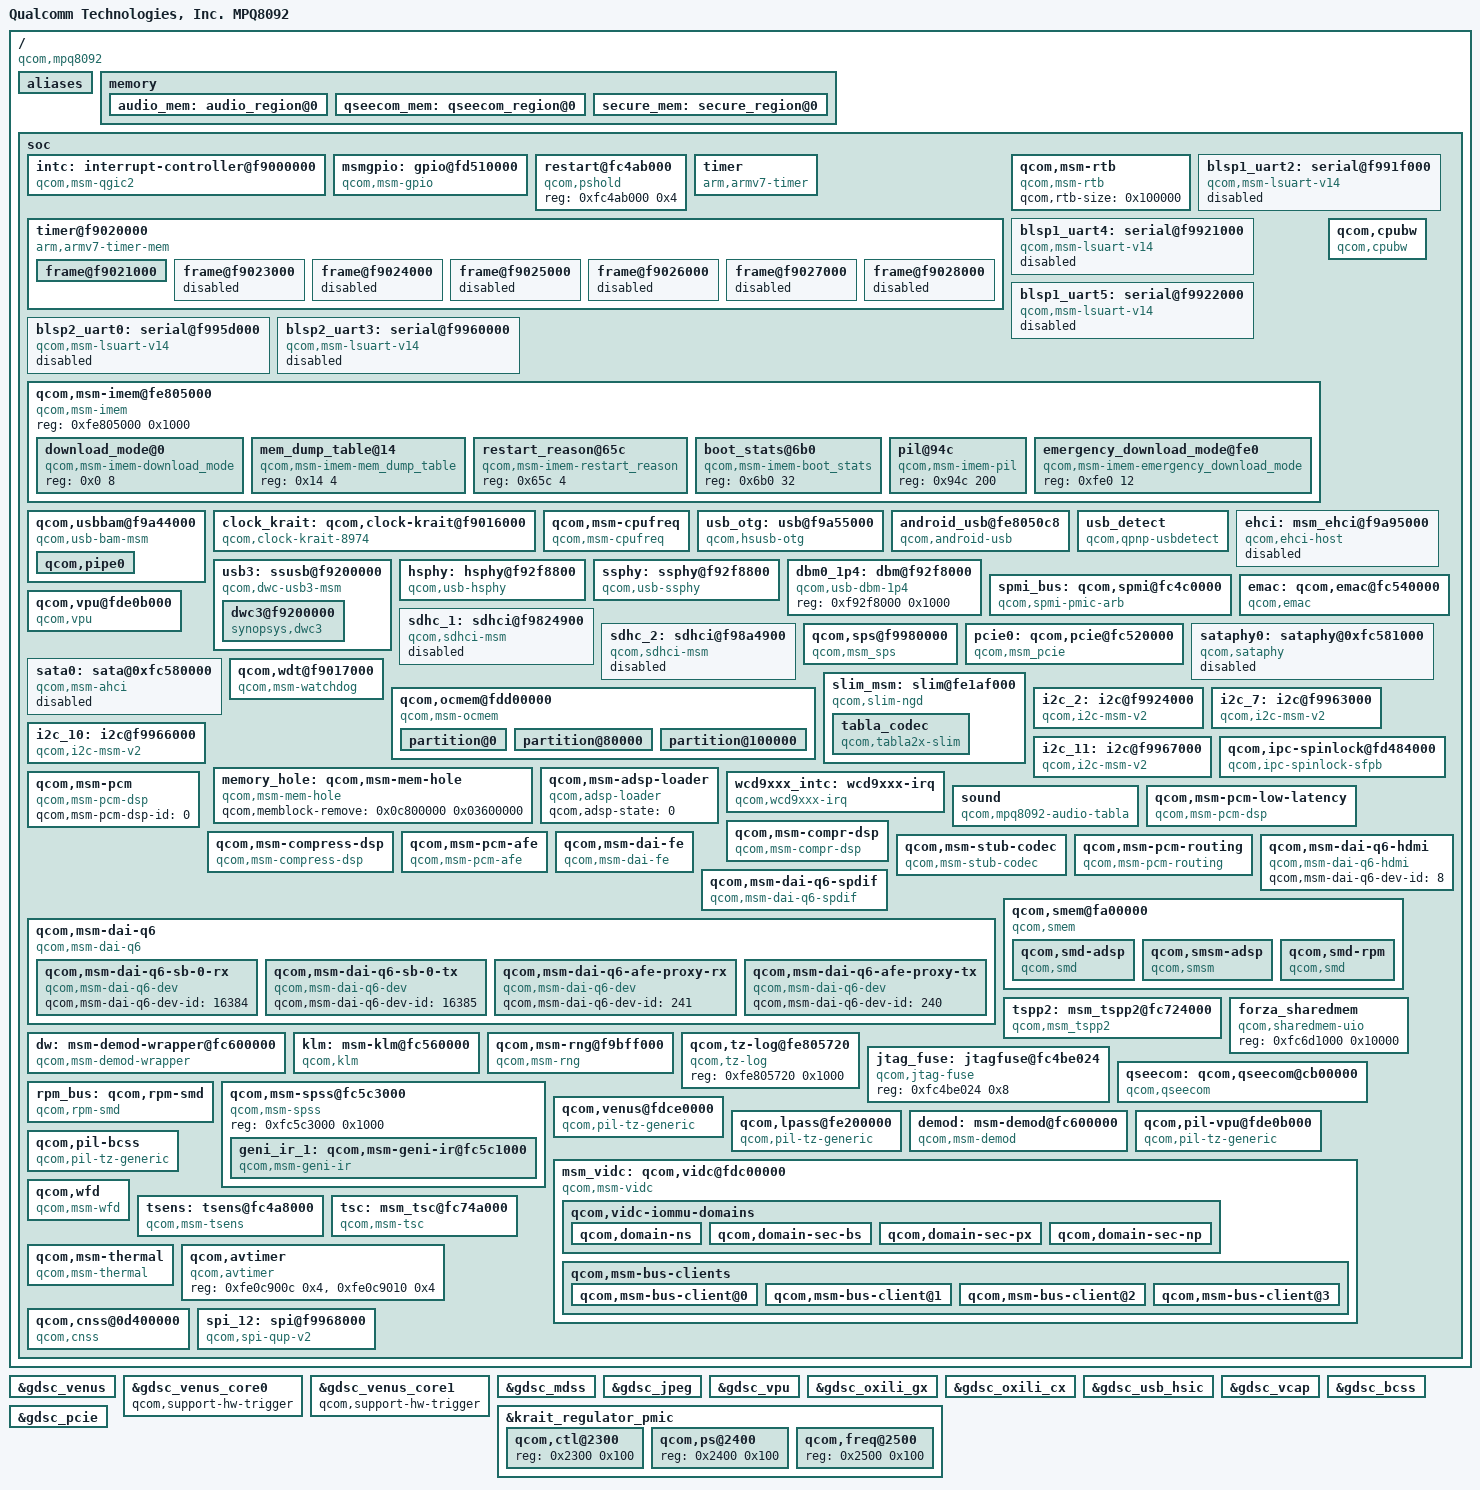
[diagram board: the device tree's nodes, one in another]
/* Copyright (c) 2012-2014, The Linux Foundation. All rights reserved.
 *
 * This program is free software; you can redistribute it and/or modify
 * it under the terms of the GNU General Public License version 2 and
 * only version 2 as published by the Free Software Foundation.
 *
 * This program is distributed in the hope that it will be useful,
 * but WITHOUT ANY WARRANTY; without even the implied warranty of
 * MERCHANTABILITY or FITNESS FOR A PARTICULAR PURPOSE.  See the
 * GNU General Public License for more details.
 */

#include "skeleton.dtsi"
#include <dt-bindings/clock/msm-clocks-krait.h>

/ {
	model = "Qualcomm Technologies, Inc. MPQ8092";
	compatible = "qcom,mpq8092";
	qcom,msm-id = <146 0>;
	interrupt-parent = <&intc>;

	aliases {
		i2c2 = &i2c_2;
		i2c7 = &i2c_7;
		i2c10 = &i2c_10;
		i2c11 = &i2c_11;
		sdhc1 = &sdhc_1; /* SDC1 eMMC slot */
		sdhc2 = &sdhc_2; /* SDC2 SD card slot */
		serial1 = &blsp2_uart0;
		serial2 = &blsp2_uart3;
		spi12 = &spi_12;
		geni_ir1 = &geni_ir_1;
	};

	memory {
		audio_mem: audio_region@0 {
			linux,reserve-contiguous-region;
			linux,reserve-region;
			reg = <0 0x614000>;
			label = "audio_mem";
		};

		qseecom_mem: qseecom_region@0 {
			linux,reserve-contiguous-region;
			reg = <0 0x1100000>;
			label = "qseecom_mem";
                };

		secure_mem: secure_region@0 {
			linux,reserve-contiguous-region;
			reg = <0 0xfc00000>;
			label = "secure_mem";
		};
	};

	soc: soc { };

};

#include "mpq8092-iommu.dtsi"
#include "mpq8092-iommu-domains.dtsi"
#include "msm-gdsc.dtsi"
#include "mpq8092-ion.dtsi"
#include "mpq8092-gpu.dtsi"
#include "mpq8092-pinctrl.dtsi"
#include "mpq8092-smp2p.dtsi"
#include "mpq8092-coresight.dtsi"
#include "mpq8092-bus.dtsi"
#include "mpq8092-pm.dtsi"
#include "mpq8092-mdss.dtsi"

&soc {
	#address-cells = <1>;
	#size-cells = <1>;
	ranges;

	intc: interrupt-controller@f9000000 {
		compatible = "qcom,msm-qgic2";
		interrupt-controller;
		#interrupt-cells = <3>;
		reg = <0xf9000000 0x1000>,
		<0xf9002000 0x1000>;
	};

	msmgpio: gpio@fd510000 {
		compatible = "qcom,msm-gpio";
		gpio-controller;
		#gpio-cells = <2>;
		interrupt-controller;
		#interrupt-cells = <2>;
		reg = <0xfd510000 0x4000>;
		ngpio = <142>;
		interrupts = <0 208 0>;
		qcom,direct-connect-irqs = <8>;
	};

	restart@fc4ab000 {
		compatible = "qcom,pshold";
		reg = <0xfc4ab000 0x4>;
	};

	timer {
		compatible = "arm,armv7-timer";
		interrupts = <1 2 0xf08>,
			     <1 3 0xf08>,
			     <1 4 0xf08>,
			     <1 1 0xf08>;
		clock-frequency = <19200000>;
	};

	timer@f9020000 {
		#address-cells = <1>;
		#size-cells = <1>;
		ranges;
		compatible = "arm,armv7-timer-mem";
		reg = <0xf9020000 0x1000>;
		clock-frequency = <19200000>;

		frame@f9021000 {
			frame-number = <0>;
			interrupts = <0 8 0x4>,
				     <0 7 0x4>;
			reg = <0xf9021000 0x1000>,
			      <0xf9022000 0x1000>;
		};

		frame@f9023000 {
			frame-number = <1>;
			interrupts = <0 9 0x4>;
			reg = <0xf9023000 0x1000>;
			status = "disabled";
		};

		frame@f9024000 {
			frame-number = <2>;
			interrupts = <0 10 0x4>;
			reg = <0xf9024000 0x1000>;
			status = "disabled";
		};

		frame@f9025000 {
			frame-number = <3>;
			interrupts = <0 11 0x4>;
			reg = <0xf9025000 0x1000>;
			status = "disabled";
		};

		frame@f9026000 {
			frame-number = <4>;
			interrupts = <0 12 0x4>;
			reg = <0xf9026000 0x1000>;
			status = "disabled";
		};

		frame@f9027000 {
			frame-number = <5>;
			interrupts = <0 13 0x4>;
			reg = <0xf9027000 0x1000>;
			status = "disabled";
		};

		frame@f9028000 {
			frame-number = <6>;
			interrupts = <0 14 0x4>;
			reg = <0xf9028000 0x1000>;
			status = "disabled";
		};
	};

	qcom,msm-rtb {
                compatible = "qcom,msm-rtb";
                qcom,rtb-size = <0x100000>;
        };

	blsp1_uart2: serial@f991f000 {
		compatible = "qcom,msm-lsuart-v14";
		reg = <0xf991f000 0x1000>;
		interrupts = <0 109 0>;
		status = "disabled";
	};

	blsp1_uart4: serial@f9921000 {
		compatible = "qcom,msm-lsuart-v14";
		reg = <0xf9921000 0x1000>;
		interrupts = <0 111 0>;
		status = "disabled";
	};

	blsp1_uart5: serial@f9922000 {
		compatible = "qcom,msm-lsuart-v14";
		reg = <0xf9922000 0x1000>;
		interrupts = <0 112 0>;
		status = "disabled";
	};

	blsp2_uart0: serial@f995d000 {
		compatible = "qcom,msm-lsuart-v14";
		reg = <0xf995d000 0x1000>;
		interrupts = <0 113 0>;
		status = "disabled";
	};

	blsp2_uart3: serial@f9960000 {
		compatible = "qcom,msm-lsuart-v14";
		reg = <0xf9960000 0x1000>;
		interrupts = <0 116 0>;
		status = "disabled";
	};

	qcom,msm-imem@fe805000 {
		compatible = "qcom,msm-imem";
		reg = <0xfe805000 0x1000>; /* Address and size of IMEM */
		ranges = <0x0 0xfe805000 0x1000>;
		#address-cells = <1>;
		#size-cells = <1>;

		download_mode@0 {
			compatible = "qcom,msm-imem-download_mode";
			reg = <0x0 8>;
		};

		mem_dump_table@14 {
			compatible = "qcom,msm-imem-mem_dump_table";
			reg = <0x14 4>;
		};

		restart_reason@65c {
			compatible = "qcom,msm-imem-restart_reason";
			reg = <0x65c 4>;
		};

		boot_stats@6b0 {
			compatible = "qcom,msm-imem-boot_stats";
			reg = <0x6b0 32>;
		};

		pil@94c {
			compatible = "qcom,msm-imem-pil";
			reg = <0x94c 200>;
		};

		emergency_download_mode@fe0 {
			compatible = "qcom,msm-imem-emergency_download_mode";
			reg = <0xfe0 12>;
		};
	};

	qcom,usbbam@f9a44000 {
		compatible = "qcom,usb-bam-msm";
		reg = <0xf9a44000 0x11000>;
		reg-names = "hsusb";
		interrupts = <0 135 0>;
		interrupt-names = "hsusb";
		qcom,usb-bam-num-pipes = <16>;
		qcom,usb-bam-fifo-baseaddr = <0xfe803000>;
		qcom,ignore-core-reset-ack;
		qcom,disable-clk-gating;

		qcom,pipe0 {
			label = "hsusb-qdss-in-0";
			qcom,usb-bam-mem-type = <3>;
			qcom,bam-type = <1>;
			qcom,dir = <1>;
			qcom,pipe-num = <0>;
			qcom,peer-bam = <1>;
			qcom,src-bam-physical-address = <0xfc37c000>;
			qcom,src-bam-pipe-index = <0>;
			qcom,dst-bam-physical-address = <0xf9a44000>;
			qcom,dst-bam-pipe-index = <2>;
			qcom,data-fifo-offset = <0x0>;
			qcom,data-fifo-size = <0x600>;
			qcom,descriptor-fifo-offset = <0x600>;
			qcom,descriptor-fifo-size = <0x200>;
		};
	};

	clock_krait: qcom,clock-krait@f9016000 {
		compatible = "qcom,clock-krait-8974";
		reg = <0xf9016000 0x20>,
			<0xf908a000 0x20>,
			<0xf909a000 0x20>,
			<0xf90aa000 0x20>,
			<0xf90ba000 0x20>,
			<0xfc4b80b0 0x08>,
			<0xf9011000 0x50>;
		reg-names = "hfpll_l2_clk", "hfpll0_clk",
				"hfpll1_clk", "hfpll2_clk",
				"hfpll3_clk", "efuse", "meas";
		cpu0-supply = <&krait0_vreg>;
		cpu1-supply = <&krait1_vreg>;
		cpu2-supply = <&krait2_vreg>;
		cpu3-supply = <&krait3_vreg>;
		l2-dig-supply = <&pma8084_s8_corner_ao>;
		hfpll-dig-supply = <&pma8084_s8_corner_ao>;
		hfpll-analog-supply = <&pma8084_l22_ao>;
		qcom,hfpll-config-val = <0x04D0405D>;
		qcom,hfpll-user-vco-mask = <0x00100000>;
		qcom,pvs-config-ver = <1>;
		#clock-cells = <1>;

		qcom,l2-fmax =
			<          0 0                   >,
			<  576000000 4 /* SVS_SOC */     >,
			< 1651200000 7 /* NORMAL & TURBO same for MPQ8092 */      >;

		qcom,speed0-pvs0-bin-v0 =
			<          0       0    0 >,
			<  300000000  850000   75 >,
			<  345600000  860000   87 >,
			<  422400000  870000  107 >,
			<  499200000  880000  128 >,
			<  576000000  890000  149 >,
			<  652800000  900000  169 >,
			<  729600000  910000  191 >,
			<  806400000  920000  213 >,
			<  883200000  930000  235 >,
			<  960000000  940000  257 >,
			< 1036800000  950000  280 >,
			< 1113600000  965000  304 >,
			< 1190400000  980000  329 >,
			< 1267200000  995000  354 >,
			< 1344000000 1010000  380 >,
			< 1420800000 1025000  406 >,
			< 1497600000 1040000  432 >,
			< 1574400000 1055000  461 >,
			< 1651200000 1070000  490 >,
			< 1728000000 1085000  520 >,
			< 1804800000 1100000  551 >;

		qcom,speed0-pvs1-bin-v0 =
			<          0       0    0 >,
			<  300000000  850000   75 >,
			<  345600000  855000   87 >,
			<  422400000  865000  107 >,
			<  499200000  875000  128 >,
			<  576000000  885000  149 >,
			<  652800000  895000  169 >,
			<  729600000  905000  191 >,
			<  806400000  915000  213 >,
			<  883200000  925000  235 >,
			<  960000000  935000  257 >,
			< 1036800000  945000  280 >,
			< 1113600000  955000  304 >,
			< 1190400000  970000  329 >,
			< 1267200000  985000  354 >,
			< 1344000000 1000000  380 >,
			< 1420800000 1015000  406 >,
			< 1497600000 1030000  432 >,
			< 1574400000 1045000  461 >,
			< 1651200000 1060000  490 >,
			< 1728000000 1075000  520 >,
			< 1804800000 1090000  551 >;

		qcom,speed0-pvs2-bin-v0 =
			<          0       0    0 >,
			<  300000000  825000   75 >,
			<  345600000  835000   87 >,
			<  422400000  845000  107 >,
			<  499200000  855000  128 >,
			<  576000000  865000  149 >,
			<  652800000  875000  169 >,
			<  729600000  885000  191 >,
			<  806400000  895000  213 >,
			<  883200000  905000  235 >,
			<  960000000  915000  257 >,
			< 1036800000  930000  280 >,
			< 1113600000  945000  304 >,
			< 1190400000  960000  329 >,
			< 1267200000  975000  354 >,
			< 1344000000  990000  380 >,
			< 1420800000 1005000  406 >,
			< 1497600000 1020000  432 >,
			< 1574400000 1035000  461 >,
			< 1651200000 1050000  490 >,
			< 1728000000 1065000  520 >,
			< 1804800000 1080000  551 >;

		qcom,speed0-pvs3-bin-v0 =
			<          0       0    0 >,
			<  300000000  825000   75 >,
			<  345600000  830000   87 >,
			<  422400000  840000  107 >,
			<  499200000  850000  128 >,
			<  576000000  860000  149 >,
			<  652800000  870000  169 >,
			<  729600000  880000  191 >,
			<  806400000  890000  213 >,
			<  883200000  900000  235 >,
			<  960000000  910000  257 >,
			< 1036800000  920000  280 >,
			< 1113600000  935000  304 >,
			< 1190400000  950000  329 >,
			< 1267200000  965000  354 >,
			< 1344000000  980000  380 >,
			< 1420800000  995000  406 >,
			< 1497600000 1010000  432 >,
			< 1574400000 1025000  461 >,
			< 1651200000 1040000  490 >,
			< 1728000000 1055000  520 >,
			< 1804800000 1070000  551 >;

		qcom,speed0-pvs4-bin-v0 =
			<          0       0    0 >,
			<  300000000  825000   75 >,
			<  345600000  825000   87 >,
			<  422400000  835000  107 >,
			<  499200000  845000  128 >,
			<  576000000  855000  149 >,
			<  652800000  865000  169 >,
			<  729600000  875000  191 >,
			<  806400000  885000  213 >,
			<  883200000  895000  235 >,
			<  960000000  905000  257 >,
			< 1036800000  915000  280 >,
			< 1113600000  925000  304 >,
			< 1190400000  940000  329 >,
			< 1267200000  955000  354 >,
			< 1344000000  970000  380 >,
			< 1420800000  985000  406 >,
			< 1497600000 1000000  432 >,
			< 1574400000 1015000  461 >,
			< 1651200000 1030000  490 >,
			< 1728000000 1045000  520 >,
			< 1804800000 1060000  551 >;

		qcom,speed0-pvs5-bin-v0 =
			<          0       0    0 >,
			<  300000000  800000   75 >,
			<  345600000  810000   87 >,
			<  422400000  820000  107 >,
			<  499200000  830000  128 >,
			<  576000000  840000  149 >,
			<  652800000  850000  169 >,
			<  729600000  860000  191 >,
			<  806400000  870000  213 >,
			<  883200000  880000  235 >,
			<  960000000  890000  257 >,
			< 1036800000  900000  280 >,
			< 1113600000  915000  304 >,
			< 1190400000  930000  329 >,
			< 1267200000  945000  354 >,
			< 1344000000  960000  380 >,
			< 1420800000  975000  406 >,
			< 1497600000  990000  432 >,
			< 1574400000 1005000  461 >,
			< 1651200000 1020000  490 >,
			< 1728000000 1035000  520 >,
			< 1804800000 1050000  551 >;

		qcom,speed0-pvs6-bin-v0 =
			<          0       0    0 >,
			<  300000000  800000   75 >,
			<  345600000  805000   87 >,
			<  422400000  815000  107 >,
			<  499200000  825000  128 >,
			<  576000000  835000  149 >,
			<  652800000  845000  169 >,
			<  729600000  855000  191 >,
			<  806400000  865000  213 >,
			<  883200000  875000  235 >,
			<  960000000  885000  257 >,
			< 1036800000  895000  280 >,
			< 1113600000  905000  304 >,
			< 1190400000  920000  329 >,
			< 1267200000  935000  354 >,
			< 1344000000  950000  380 >,
			< 1420800000  965000  406 >,
			< 1497600000  980000  432 >,
			< 1574400000  995000  461 >,
			< 1651200000 1010000  490 >,
			< 1728000000 1025000  520 >,
			< 1804800000 1040000  551 >;

		qcom,speed0-pvs7-bin-v0 =
			<          0       0    0 >,
			<  300000000  800000   75 >,
			<  345600000  800000   87 >,
			<  422400000  805000  107 >,
			<  499200000  815000  128 >,
			<  576000000  825000  149 >,
			<  652800000  835000  169 >,
			<  729600000  845000  191 >,
			<  806400000  855000  213 >,
			<  883200000  865000  235 >,
			<  960000000  875000  257 >,
			< 1036800000  885000  280 >,
			< 1113600000  895000  304 >,
			< 1190400000  910000  329 >,
			< 1267200000  925000  354 >,
			< 1344000000  940000  380 >,
			< 1420800000  955000  406 >,
			< 1497600000  970000  432 >,
			< 1574400000  985000  461 >,
			< 1651200000 1000000  490 >,
			< 1728000000 1015000  520 >,
			< 1804800000 1030000  551 >;

		qcom,speed0-pvs8-bin-v0 =
			<          0       0    0 >,
			<  300000000  775000   75 >,
			<  345600000  780000   87 >,
			<  422400000  790000  107 >,
			<  499200000  800000  128 >,
			<  576000000  810000  149 >,
			<  652800000  820000  169 >,
			<  729600000  830000  191 >,
			<  806400000  840000  213 >,
			<  883200000  850000  235 >,
			<  960000000  860000  257 >,
			< 1036800000  870000  280 >,
			< 1113600000  885000  304 >,
			< 1190400000  900000  329 >,
			< 1267200000  915000  354 >,
			< 1344000000  930000  380 >,
			< 1420800000  945000  406 >,
			< 1497600000  960000  432 >,
			< 1574400000  975000  461 >,
			< 1651200000  990000  490 >,
			< 1728000000 1005000  520 >,
			< 1804800000 1020000  551 >;

		qcom,speed0-pvs9-bin-v0 =
			<          0       0    0 >,
			<  300000000  775000   75 >,
			<  345600000  775000   87 >,
			<  422400000  785000  107 >,
			<  499200000  795000  128 >,
			<  576000000  805000  149 >,
			<  652800000  815000  169 >,
			<  729600000  825000  191 >,
			<  806400000  835000  213 >,
			<  883200000  845000  235 >,
			<  960000000  855000  257 >,
			< 1036800000  865000  280 >,
			< 1113600000  875000  304 >,
			< 1190400000  890000  329 >,
			< 1267200000  905000  354 >,
			< 1344000000  920000  380 >,
			< 1420800000  935000  406 >,
			< 1497600000  950000  432 >,
			< 1574400000  965000  461 >,
			< 1651200000  980000  490 >,
			< 1728000000  995000  520 >,
			< 1804800000 1010000  551 >;

		qcom,speed0-pvs10-bin-v0 =
			<          0       0    0 >,
			<  300000000  775000   75 >,
			<  345600000  775000   87 >,
			<  422400000  780000  107 >,
			<  499200000  790000  128 >,
			<  576000000  800000  149 >,
			<  652800000  810000  169 >,
			<  729600000  820000  191 >,
			<  806400000  830000  213 >,
			<  883200000  840000  235 >,
			<  960000000  850000  257 >,
			< 1036800000  860000  280 >,
			< 1113600000  870000  304 >,
			< 1190400000  880000  329 >,
			< 1267200000  895000  354 >,
			< 1344000000  910000  380 >,
			< 1420800000  925000  406 >,
			< 1497600000  940000  432 >,
			< 1574400000  955000  461 >,
			< 1651200000  970000  490 >,
			< 1728000000  985000  520 >,
			< 1804800000 1000000  551 >;

		qcom,speed0-pvs11-bin-v0 =
			<          0       0    0 >,
			<  300000000  750000   75 >,
			<  345600000  755000   87 >,
			<  422400000  765000  107 >,
			<  499200000  775000  128 >,
			<  576000000  785000  149 >,
			<  652800000  795000  169 >,
			<  729600000  805000  191 >,
			<  806400000  815000  213 >,
			<  883200000  825000  235 >,
			<  960000000  835000  257 >,
			< 1036800000  845000  280 >,
			< 1113600000  855000  304 >,
			< 1190400000  870000  329 >,
			< 1267200000  885000  354 >,
			< 1344000000  900000  380 >,
			< 1420800000  915000  406 >,
			< 1497600000  930000  432 >,
			< 1574400000  945000  461 >,
			< 1651200000  960000  490 >,
			< 1728000000  975000  520 >,
			< 1804800000  990000  551 >;

		qcom,speed0-pvs12-bin-v0 =
			<          0       0    0 >,
			<  300000000  750000   75 >,
			<  345600000  750000   87 >,
			<  422400000  755000  107 >,
			<  499200000  765000  128 >,
			<  576000000  775000  149 >,
			<  652800000  785000  169 >,
			<  729600000  795000  191 >,
			<  806400000  805000  213 >,
			<  883200000  815000  235 >,
			<  960000000  825000  257 >,
			< 1036800000  835000  280 >,
			< 1113600000  845000  304 >,
			< 1190400000  860000  329 >,
			< 1267200000  875000  354 >,
			< 1344000000  890000  380 >,
			< 1420800000  905000  406 >,
			< 1497600000  920000  432 >,
			< 1574400000  935000  461 >,
			< 1651200000  950000  490 >,
			< 1728000000  965000  520 >,
			< 1804800000  980000  551 >;

		qcom,speed0-pvs13-bin-v0 =
			<          0       0    0 >,
			<  300000000  750000   75 >,
			<  345600000  750000   87 >,
			<  422400000  750000  107 >,
			<  499200000  760000  128 >,
			<  576000000  770000  149 >,
			<  652800000  780000  169 >,
			<  729600000  790000  191 >,
			<  806400000  800000  213 >,
			<  883200000  810000  235 >,
			<  960000000  820000  257 >,
			< 1036800000  830000  280 >,
			< 1113600000  840000  304 >,
			< 1190400000  850000  329 >,
			< 1267200000  865000  354 >,
			< 1344000000  880000  380 >,
			< 1420800000  895000  406 >,
			< 1497600000  910000  432 >,
			< 1574400000  925000  461 >,
			< 1651200000  940000  490 >,
			< 1728000000  955000  520 >,
			< 1804800000  970000  551 >;

		qcom,speed0-pvs14-bin-v0 =
			<          0       0    0 >,
			<  300000000  750000   75 >,
			<  345600000  750000   87 >,
			<  422400000  750000  107 >,
			<  499200000  750000  128 >,
			<  576000000  760000  149 >,
			<  652800000  770000  169 >,
			<  729600000  780000  191 >,
			<  806400000  790000  213 >,
			<  883200000  800000  235 >,
			<  960000000  810000  257 >,
			< 1036800000  820000  280 >,
			< 1113600000  830000  304 >,
			< 1190400000  840000  329 >,
			< 1267200000  855000  354 >,
			< 1344000000  870000  380 >,
			< 1420800000  885000  406 >,
			< 1497600000  900000  432 >,
			< 1574400000  915000  461 >,
			< 1651200000  930000  490 >,
			< 1728000000  945000  520 >,
			< 1804800000  960000  551 >;

		qcom,speed0-pvs15-bin-v0 =
			<          0       0    0 >,
			<  300000000  750000   75 >,
			<  345600000  750000   87 >,
			<  422400000  750000  107 >,
			<  499200000  750000  128 >,
			<  576000000  750000  149 >,
			<  652800000  760000  169 >,
			<  729600000  770000  191 >,
			<  806400000  780000  213 >,
			<  883200000  790000  235 >,
			<  960000000  800000  257 >,
			< 1036800000  810000  280 >,
			< 1113600000  820000  304 >,
			< 1190400000  830000  329 >,
			< 1267200000  845000  354 >,
			< 1344000000  860000  380 >,
			< 1420800000  875000  406 >,
			< 1497600000  890000  432 >,
			< 1574400000  905000  461 >,
			< 1651200000  920000  490 >,
			< 1728000000  935000  520 >,
			< 1804800000  950000  551 >;
	};

	qcom,cpubw {
		compatible = "qcom,cpubw";
		qcom,cpu-mem-ports = <1 512>;
		qcom,bw-tbl =
			<  8117 /*  532 MHz */ >;
	};

	qcom,msm-cpufreq {
		compatible = "qcom,msm-cpufreq";
		clock-names = "l2_clk", "cpu0_clk", "cpu1_clk", "cpu2_clk",
				"cpu3_clk";
		clocks = <&clock_krait clk_l2_clk>,
			 <&clock_krait clk_krait0_clk>,
			 <&clock_krait clk_krait1_clk>,
			 <&clock_krait clk_krait2_clk>,
			 <&clock_krait clk_krait3_clk>;
		qcom,cpufreq-table =
			<  300000  300000  8117 >,
			<  345600  345600  8117 >,
			<  422400  422400  8117 >,
			<  499200  499400  8117 >,
			<  576000  576000  8117 >,
			<  652800  652800  8117 >,
			<  729600  729600  8117 >,
			<  806400  806400  8117 >,
			<  883200  883200  8117 >,
			<  960000  960000  8117 >,
			< 1036800 1036800  8117 >,
			< 1113600 1113600  8117 >,
			< 1190400 1190400  8117 >,
			< 1267200 1267200  8117 >,
			< 1344000 1344000  8117 >,
			< 1420800 1420800  8117 >,
			< 1497600 1497600  8117 >,
			< 1574400 1574400  8117 >,
			< 1651200 1651200  8117 >,
			< 1728000 1651200  8117 >,
			< 1804800 1651200  8117 >;
	};

	usb_otg: usb@f9a55000 {
		compatible = "qcom,hsusb-otg";
		reg = <0xf9a55000 0x400>,
			 <0xfd4ab000 0x4>;
		interrupts = <0 134 0>, <0 140 0>;
		interrupt-names = "core_irq", "async_irq";

		hsusb_vdd_dig-supply = <&pma8084_s8_corner>;
		HSUSB_1p8-supply = <&pma8084_l22>;
		HSUSB_3p3-supply = <&pma8084_l24>;
		qcom,vdd-voltage-level = <1 5 7>;

		qcom,hsusb-otg-phy-type = <2>;
		qcom,hsusb-otg-mode = <1>;
		qcom,hsusb-otg-otg-control = <2>;
		qcom,hsusb-otg-disable-reset;
		qcom,dp-manual-pullup;
		qcom,usb2-enable-hsphy2;

		qcom,msm-bus,name = "usb_otg";
		qcom,msm-bus,num_cases = <3>;
		qcom,msm-bus,active_only = <0>;
		qcom,msm-bus,num_paths = <1>;
		qcom,msm-bus,vectors-KBps =
				<87 512 0 0>,
				<87 512 60000 960000>,
				<87 512 6000  6000>;
	};

	android_usb@fe8050c8 {
		compatible = "qcom,android-usb";
		reg = <0xfe8050c8 0xc8>;
		qcom,android-usb-swfi-latency = <1>;
	};

	usb_detect {
		compatible = "qcom,qpnp-usbdetect";
		interrupt-parent = <&spmi_bus>;
		interrupts = <0x0 0xca 0x0>;  /* PMA8084 GPIO 11 */
		interrupt-names = "vbus_det_irq";
		vin-supply = <&smb210_vreg>;
	};

	ehci: msm_ehci@f9a95000 {
		compatible = "qcom,ehci-host";
		status = "disabled";
		reg = <0xf9a95000 0x400>;
		interrupts = <0 293 0>, <0 294 0>;
		interrupt-names = "core_irq", "async_irq";
		HSUSB_VDDCX-supply = <&pma8084_s8_corner>;
		qcom,vdd-voltage-level = <1 2 3 5 7>;
		HSUSB_1p8-supply = <&pma8084_l22>;
		HSUSB_3p3-supply = <&pma8084_l24>;
		qcom,usb2-power-budget = <500>;
	};

	usb3: ssusb@f9200000 {
		compatible = "qcom,dwc-usb3-msm";
		reg = <0xf9200000 0xfc000>,
			  <0xfd4ab000 0x4>;
		#address-cells = <1>;
		#size-cells = <1>;
		ranges;

		interrupts = <0 133 0>;
		interrupt-names = "hs_phy_irq";

		vbus_dwc3-supply = <&usb3_otg>;
		qcom,charging-disabled;
		qcom,dwc-usb3-msm-tx-fifo-size = <29696>;
		qcom,dwc-usb3-msm-qdss-tx-fifo-size = <8192>;
		qcom,usb-dbm = <&dbm0_1p4>;

		qcom,msm-bus,name = "usb3";
		qcom,msm-bus,num-cases = <2>;
		qcom,msm-bus,num-paths = <1>;
		qcom,msm-bus,vectors-KBps =
				<61 512 0 0>,
				<61 512 240000 960000>;
		dwc3@f9200000 {
			compatible = "synopsys,dwc3";
			reg = <0xf9200000 0xfc000>;
			interrupt-parent = <&intc>;
			interrupts = <0 131 0>, <0 179 0>;
			interrupt-names = "irq", "otg_irq";
			usb-phy = <&hsphy>, <&ssphy>;
			tx-fifo-resize;
			host-only-mode;
		};
	};

	hsphy: hsphy@f92f8800 {
		compatible = "qcom,usb-hsphy";
		reg = <0xf92f8800 0x3ff>;
		qcom,hsphy-init = <0x00D191A4>;
		vdd-supply = <&pma8084_s8_corner>;
		vdda18-supply = <&pma8084_l22>;
		vdda33-supply = <&pma8084_l24>;
		qcom,vdd-voltage-level = <1 5 7>;
		qcom,ext-vbus-id;
	};

	ssphy: ssphy@f92f8800 {
		compatible = "qcom,usb-ssphy";
		reg = <0xf92f8800 0x3ff>;
		vdd-supply = <&pma8084_s8_corner>;
		vdda18-supply = <&pma8084_l22>;
		vdda33-supply = <&pma8084_l24>;
		qcom,vdd-voltage-level = <1 5 7>;
	};

	dbm0_1p4: dbm@f92f8000 {
		compatible = "qcom,usb-dbm-1p4";
		reg = <0xf92f8000 0x1000>;
	};

	spmi_bus: qcom,spmi@fc4c0000 {
		cell-index = <0>;
		compatible = "qcom,spmi-pmic-arb";
		reg-names = "core", "intr", "cnfg";
		reg = <0xfc4cf000 0x1000>,
		      <0Xfc4cb000 0x1000>,
		      <0Xfc4ca000 0x1000>;
		/* 190,ee0_krait_hlos_spmi_periph_irq */
		/* 187,channel_0_krait_hlos_trans_done_irq */
		interrupts = <0 190 0 0 187 0>;
		qcom,not-wakeup;
		qcom,pmic-arb-ee = <0>;
		qcom,pmic-arb-channel = <0>;
	};

	emac: qcom,emac@fc540000 {
		cell-index = <0>;
		compatible = "qcom,emac";
		reg-names = "emac", "emac_csr";
		reg = <0xfc540000 0x10000>,
		      <0xfc556000 0x1000>;
		interrupts = <0 291 0>,
			     <0 290 0>,
			     <0 317 0>,
			     <0 318 0>;
		interrupt-names = "emac_core0_irq",
				  "emac_core1_irq",
				  "emac_core2_irq",
				  "emac_core3_irq";
		phy-mode = "rgmii";
		phy-addr = <4>;
	};

	qcom,vpu@fde0b000 {
		compatible = "qcom,vpu";
		reg = <0xfde0b000 0x1000>,
			<0x0f800000 0x200000>;
		reg-names = "vpu_csr", "vpu_smem";
		interrupts = <0 299 0>, <0 298 0>;
		interrupt-names = "vpu_wdog", "vpu_hfi";
		qcom,clock-names = "vdp_bus_clk", "core_clk", "vdp_clk",
			"iface_clk", "bus_clk", "sleep_clk", "cxo_clk",
			"maple_bus_clk", "prng_clk", "vdp_xin_clk";
		qcom,bus-load-vector-tbl = <0 0 0>,
			<36000  208000  303000>,
			<110400 536000  303000>,
			<244800 1012000 303000>,
			<489000 2024000 606000>,
			<783360 3240000 970000>,
			<979200 4048000 1212000>,
			<9792000 4264000 12790000>;
		qcom,enabled-iommu-maps = "vpu_nonsecure", "vpu_secure";
		vdd-supply = <&gdsc_vpu>;
	};

	sdhc_1: sdhci@f9824900 {
		compatible = "qcom,sdhci-msm";
		reg = <0xf9824900 0x11c>, <0xf9824000 0x800>;
		reg-names = "hc_mem", "core_mem";

		interrupts = <0 123 0>, <0 138 0>;
		interrupt-names = "hc_irq", "pwr_irq";

		qcom,bus-width = <8>;

		qcom,msm-bus,name = "sdhc1";
		qcom,msm-bus,num-cases = <8>;
		qcom,msm-bus,num-paths = <1>;
		qcom,msm-bus,vectors-KBps = <78 512 0 0>, /* No vote */
				<78 512 1600 3200>,    /* 400 KB/s*/
				<78 512 80000 160000>, /* 20 MB/s */
				<78 512 100000 200000>, /* 25 MB/s */
				<78 512 200000 400000>, /* 50 MB/s */
				<78 512 400000 800000>, /* 100 MB/s */
				<78 512 400000 800000>, /* 200 MB/s */
				<78 512 2048000 4096000>; /* Max. bandwidth */
		qcom,bus-bw-vectors-bps = <0 400000 20000000 25000000 50000000
						100000000 200000000 4294967295>;

		status = "disabled";
	};

	sdhc_2: sdhci@f98a4900 {
		compatible = "qcom,sdhci-msm";
		reg = <0xf98a4900 0x11c>, <0xf98a4000 0x800>;
		reg-names = "hc_mem", "core_mem";

		interrupts = <0 125 0>, <0 221 0>;
		interrupt-names = "hc_irq", "pwr_irq";

		qcom,bus-width = <4>;

		qcom,msm-bus,name = "sdhc2";
		qcom,msm-bus,num-cases = <8>;
		qcom,msm-bus,num-paths = <1>;
		qcom,msm-bus,vectors-KBps = <81 512 0 0>, /* No vote */
				<81 512 1600 3200>,    /* 400 KB/s*/
				<81 512 80000 160000>, /* 20 MB/s */
				<81 512 100000 200000>, /* 25 MB/s */
				<81 512 200000 400000>, /* 50 MB/s */
				<81 512 400000 800000>, /* 100 MB/s */
				<81 512 400000 800000>, /* 200 MB/s */
				<81 512 2048000 4096000>; /* Max. bandwidth */
		qcom,bus-bw-vectors-bps = <0 400000 20000000 25000000 50000000
						100000000 200000000 4294967295>;

		status = "disabled";
	};

	qcom,sps@f9980000 {
		compatible = "qcom,msm_sps";
		reg = <0xf9984000 0x15000>,
		      <0xf9999000 0xb000>;
		reg-names = "bam_mem", "core_mem";
		interrupts = <0 94 0>;
		qcom,pipe-attr-ee;
	};

	pcie0: qcom,pcie@fc520000 {
		compatible = "qcom,msm_pcie";
		cell-index = <0>;
		qcom,ctrl-amt = <1>;

		reg = <0xfc520000 0x2000>,
		      <0xfc526000 0x1000>,
		      <0xff000000 0x1000>,
		      <0xff001000 0x1000>,
		      <0xff100000 0x1000>,
		      <0xff200000 0x100000>,
		      <0xff300000 0xd00000>;

		reg-names = "parf", "phy", "dm_core", "elbi",
				"conf", "io", "bars";

		#address-cells = <0>;
		interrupt-parent = <&pcie0>;
		interrupts = <0 1 2 3 4 5 6 7 8 9 10 11 12>;
		#interrupt-cells = <1>;
		interrupt-map-mask = <0xffffffff>;
		interrupt-map = <0 &intc 0 248 0
				1 &intc 0 249 0
				2 &intc 0 250 0
				3 &intc 0 251 0
				4 &intc 0 252 0
				5 &intc 0 253 0
				6 &intc 0 254 0
				7 &intc 0 255 0
				8 &intc 0 256 0
				9 &intc 0 257 0
				10 &intc 0 258 0
				11 &intc 0 259 0
				12 &msmgpio 53 0x2>;
		interrupt-names = "int_msi", "int_a", "int_b", "int_c", "int_d",
				"int_pls_pme", "int_pme_legacy", "int_pls_err",
				"int_aer_legacy", "int_pls_link_up",
				"int_pls_link_down", "int_bridge_flush_n",
				"int_wake";

		perst-gpio = <&msmgpio 54 0>;
		wake-gpio = <&msmgpio 53 0>;
		clkreq-gpio = <&msmgpio 52 0>;

		gdsc-vdd-supply = <&gdsc_pcie>;
		vreg-1.8-supply = <&pma8084_l22>;
		vreg-0.9-supply = <&pma8084_l19>;

		qcom,vreg-0.9-voltage-level = <950000 950000 24000>;
	};

	sataphy0: sataphy@0xfc581000 {
		compatible = "qcom,sataphy";
		reg = <0xfc581000 0x400>;
		reg-names = "phy_mem";
		#phy-cells = <0>;
		vdda-phy-supply = <&pma8084_l19>;
		vdda-pll-supply = <&pma8084_l22>;
		vdda-phy-max-microamp = <50000>;
		vdda-pll-max-microamp = <12000>;

		status = "disabled";
	};

	sata0: sata@0xfc580000 {
		compatible = "qcom,msm-ahci";
		reg = <0xfc580000 0x400>;
		interrupts = <0 292 0>;

		phys = <&sataphy0>;
		phy-names = "sata-6g";
		clock-names = "core_clk", "iface_clk", "pmalive_clk",
				"rxoob_clk", "asic0_clk", "rbc0_clk";
		max-clock-frequency-hz = <0 0 100000000
					100000000 300000000 300000000>;
		status = "disabled";
	};

	qcom,wdt@f9017000 {
		compatible = "qcom,msm-watchdog";
		reg = <0xf9017000 0x1000>;
		interrupts = <0 3 0>, <0 4 0>;
		qcom,bark-time = <11000>;
		qcom,pet-time = <10000>;
		qcom,ipi-ping;
	};

	qcom,ocmem@fdd00000 {
		compatible = "qcom,msm-ocmem";
		reg = <0xfdd00000 0x2000>,
		      <0xfdd02000 0x2000>,
		      <0xfe070000 0x400>,
		      <0xfec00000 0x180000>;
		reg-names = "ocmem_ctrl_physical", "dm_ctrl_physical", "br_ctrl_physical", "ocmem_physical";
		interrupts = <0 76 0>, <0 77 0>;
		interrupt-names = "ocmem_irq", "dm_irq";
		qcom,ocmem-num-regions = <0x3>;
		qcom,ocmem-num-macros = <0x18>;
		qcom,resource-type = <0x706d636f>;
		#address-cells = <1>;
		#size-cells = <1>;
		ranges = <0x0 0xfec00000 0x180000>;

		partition@0 {
			reg = <0x0 0x100000>;
			qcom,ocmem-part-name = "graphics";
			qcom,ocmem-part-min = <0x80000>;
		};

		partition@80000 {
			reg = <0x100000 0x80000>;
			qcom,ocmem-part-name = "lp_audio";
			qcom,ocmem-part-min = <0x80000>;
		};

		partition@100000 {
			reg = <0x100000 0x80000>;
			qcom,ocmem-part-name = "video";
			qcom,ocmem-part-min = <0x55000>;
		};
	};

	slim_msm: slim@fe1af000 {
		cell-index = <1>;
		compatible = "qcom,slim-ngd";
		reg = <0xfe1af000 0x35000>,
		     <0xfe184000 0x20000>;
		reg-names = "slimbus_physical", "slimbus_bam_physical";
		interrupts = <0 163 0 0 164 0>;
		interrupt-names = "slimbus_irq", "slimbus_bam_irq";
		qcom,apps-ch-pipes = <0x60000000>;
		qcom,ea-pc = <0xc0>;
	};

	i2c_2: i2c@f9924000 { /* BLSP1 QUP2 */
		compatible = "qcom,i2c-msm-v2";
		#address-cells = <1>;
		#size-cells = <0>;
		reg-names = "qup_phys_addr", "bam_phys_addr";
		reg = <0xf9924000 0x1000>,
		      <0xf9904000 0x19000>;
		interrupt-names = "qup_irq", "bam_irq";
		interrupts = <0 96 0>, <0 238 0>;
		qcom,clk-freq-out = <100000>;
		qcom,clk-freq-in  = <19200000>;
		qcom,gpio-sda = <&msmgpio 6 0>;
		qcom,gpio-scl = <&msmgpio 7 0>;
		qcom,noise-rjct-scl = <0>;
		qcom,noise-rjct-sda = <0>;
		qcom,bam-pipe-idx-cons = <14>;
		qcom,bam-pipe-idx-prod = <15>;
		qcom,master-id = <86>;
	};

	i2c_7: i2c@f9963000 { /* BLSP2 QUP0 */
		compatible = "qcom,i2c-msm-v2";
		#address-cells = <1>;
		#size-cells = <0>;
		reg-names = "qup_phys_addr", "bam_phys_addr";
		reg = <0xf9963000 0x1000>,
		      <0xf9944000 0x19000>;
		interrupt-names = "qup_irq", "bam_irq";
		interrupts = <0 101 0>, <0 239 0>;
		qcom,clk-freq-out = <100000>;
		qcom,clk-freq-in  = <19200000>;
		qcom,gpio-sda = <&msmgpio 14 0>;
		qcom,gpio-scl = <&msmgpio 15 0>;
		qcom,noise-rjct-scl = <0>;
		qcom,noise-rjct-sda = <0>;
		qcom,bam-pipe-idx-cons = <12>;
		qcom,bam-pipe-idx-prod = <13>;
		qcom,master-id = <84>;
	};

	i2c_10: i2c@f9966000 { /* BLSP2 QUP4 */
		compatible = "qcom,i2c-msm-v2";
		#address-cells = <1>;
		#size-cells = <0>;
		reg-names = "qup_phys_addr", "bam_phys_addr";
		reg = <0xf9966000 0x1000>,
		      <0xf9944000 0x19000>;
		interrupt-names = "qup_irq", "bam_irq";
		interrupts = <0 104 0>, <0 239 0>;
		qcom,clk-freq-out = <100000>;
		qcom,clk-freq-in  = <19200000>;
		qcom,gpio-sda = <&msmgpio 61 0>;
		qcom,gpio-scl = <&msmgpio 62 0>;
		qcom,noise-rjct-scl = <0>;
		qcom,noise-rjct-sda = <0>;
		qcom,bam-pipe-idx-cons = <18>;
		qcom,bam-pipe-idx-prod = <19>;
		qcom,master-id = <84>;
	};

	i2c_11: i2c@f9967000 { /* BLSP2 QUP5 */
		compatible = "qcom,i2c-msm-v2";
		#address-cells = <1>;
		#size-cells = <0>;
		reg-names = "qup_phys_addr", "bam_phys_addr";
		reg = <0xf9967000 0x1000>,
		      <0xf9944000 0x19000>;
		interrupt-names = "qup_irq", "bam_irq";
		interrupts = <0 105 0>, <0 239 0>;
		qcom,clk-freq-out = <100000>;
		qcom,clk-freq-in  = <19200000>;
		qcom,gpio-sda = <&msmgpio 81 0>;
		qcom,gpio-scl = <&msmgpio 82 0>;
		qcom,noise-rjct-scl = <0>;
		qcom,noise-rjct-sda = <0>;
		qcom,bam-pipe-idx-cons = <20>;
		qcom,bam-pipe-idx-prod = <21>;
		qcom,master-id = <84>;
	};

	memory_hole: qcom,msm-mem-hole {
		compatible = "qcom,msm-mem-hole";
		qcom,memblock-remove = <0x0c800000 0x03600000>;
	};

	qcom,ipc-spinlock@fd484000 {
		compatible = "qcom,ipc-spinlock-sfpb";
		reg = <0xfd484000 0x400>;
		qcom,num-locks = <8>;
	};

	qcom,msm-adsp-loader {
		compatible = "qcom,adsp-loader";
		qcom,adsp-state = <0>;
	};

	wcd9xxx_intc: wcd9xxx-irq {
		compatible = "qcom,wcd9xxx-irq";
		interrupt-controller;
		#interrupt-cells = <1>;
		interrupt-parent = <&msmgpio>;
		interrupts = <45 0>;
		interrupt-names = "cdc-int";
	};

	slim_msm: slim@fe1af000 {
		cell-index = <1>;
		compatible = "qcom,slim-ngd";
		reg = <0xfe1af000 0x35000>,
		      <0xfe184000 0x20000>;
		reg-names = "slimbus_physical", "slimbus_bam_physical";
		interrupts = <0 163 0 0 164 0>;
		interrupt-names = "slimbus_irq", "slimbus_bam_irq";
		qcom,apps-ch-pipes = <0x60000000>;
		qcom,ea-pc = <0xc0>;

		tabla_codec {
			compatible = "qcom,tabla2x-slim";
			elemental-addr = [00 01 60 00 17 02];

			interrupt-parent = <&wcd9xxx_intc>;
			interrupts = <0 1 2 3 4 5 6 7 8 9 10 11 12 13 14 15 16
				      17 18 19 20 21>;

			cdc-vdd-buck-supply = <&pma8084_s5>;
			qcom,cdc-vdd-buck-voltage = <2150000 2150000>;
			qcom,cdc-vdd-buck-current = <650000>;

			cdc-vdd-tx-h-supply = <&pma8084_s4>;
			qcom,cdc-vdd-tx-h-voltage = <1800000 1800000>;
			qcom,cdc-vdd-tx-h-current = <25000>;

			cdc-vdd-rx-h-supply = <&pma8084_s4>;
			qcom,cdc-vdd-rx-h-voltage = <1800000 1800000>;
			qcom,cdc-vdd-rx-h-current = <25000>;

			cdc-vddpx-1-supply = <&pma8084_s4>;
			qcom,cdc-vddpx-1-voltage = <1800000 1800000>;
			qcom,cdc-vddpx-1-current = <10000>;

			cdc-vdd-a-1p2v-supply = <&pma8084_l1>;
			qcom,cdc-vdd-a-1p2v-voltage = <1225000 1225000>;
			qcom,cdc-vdd-a-1p2v-current = <10000>;

			cdc-vddcx-1-supply = <&pma8084_l1>;
			qcom,cdc-vddcx-1-voltage = <1225000 1225000>;
			qcom,cdc-vddcx-1-current = <10000>;

			qcom,cdc-static-supplies = "cdc-vdd-buck",
				"cdc-vdd-tx-h",
				"cdc-vdd-rx-h",
				"cdc-vddpx-1",
				"cdc-vdd-a-1p2v",
				"cdc-vddcx-1";

			qcom,cdc-micbias-ldoh-v = <0x3>;
			qcom,cdc-micbias-cfilt1-mv = <1800>;
			qcom,cdc-micbias-cfilt2-mv = <1800>;
			qcom,cdc-micbias-cfilt3-mv = <1800>;
			qcom,cdc-micbias1-cfilt-sel = <0x0>;
			qcom,cdc-micbias2-cfilt-sel = <0x1>;
			qcom,cdc-micbias3-cfilt-sel = <0x2>;
			qcom,cdc-micbias4-cfilt-sel = <0x2>;

			qcom,cdc-reset-gpio = <&msmgpio 36 0>;

			qcom,cdc-mclk-clk-rate = <12288000>;
			qcom,cdc-slim-ifd = "tabla-slave";
			qcom,cdc-slim-ifd-elemental-addr = [00 00 60 00 17 02];
		};
	};

	sound {
		compatible = "qcom,mpq8092-audio-tabla";
		qcom,model = "mpq8092-tabla-snd-card";

		qcom,audio-routing =
			"RX_BIAS", "MCLK",
			"LDO_H", "MCLK",
			"AMIC1", "MIC BIAS1 External",
			"MIC BIAS1 External", "Handset Mic",
			"AMIC2", "MIC BIAS2 External",
			"MIC BIAS2 External", "Headset Mic",
			"AMIC3", "MIC BIAS3 External",
			"MIC BIAS3 Eternal", "ANCRight Headset Mic",
			"AMIC4", "MIC BIAS1 External",
			"MIC BIAS1 External", "ANCLeft Headset Mic",
                        "HEADPHONE", "LDO_H";

		qcom,cdc-mclk-gpios = <&msmgpio 42 0>;
		qcom,tabla-mclk-clk-freq = <12288000>;
		qcom,spdif-opt-gpio = <&msmgpio 46 0>;
		qcom,spdif-elec-gpio = <&msmgpio 41 0>;
		qcom,hdmi-audio-rx;
		qcom,spdif-audio-rx;
	};

	qcom,msm-pcm-low-latency {
		compatible = "qcom,msm-pcm-dsp";
		qcom,msm-pcm-dsp-id = <1>;
		qcom,msm-pcm-low-latency;
	};

	qcom,msm-pcm {
		compatible = "qcom,msm-pcm-dsp";
		qcom,msm-pcm-dsp-id = <0>;
	};

	qcom,msm-compr-dsp {
		compatible = "qcom,msm-compr-dsp";
	};

	qcom,msm-compress-dsp {
		compatible = "qcom,msm-compress-dsp";
	};

	qcom,msm-pcm-afe {
		compatible = "qcom,msm-pcm-afe";
	};

	qcom,msm-dai-fe {
		compatible = "qcom,msm-dai-fe";
	};

	qcom,msm-stub-codec {
		compatible = "qcom,msm-stub-codec";
	};

	qcom,msm-pcm-routing {
		compatible = "qcom,msm-pcm-routing";
	};

	qcom,msm-dai-q6-hdmi {
		compatible = "qcom,msm-dai-q6-hdmi";
		qcom,msm-dai-q6-dev-id = <8>;
	};

	qcom,msm-dai-q6-spdif {
		compatible = "qcom,msm-dai-q6-spdif";
	};

	qcom,msm-dai-q6 {
		compatible = "qcom,msm-dai-q6";

		qcom,msm-dai-q6-sb-0-rx {
			compatible = "qcom,msm-dai-q6-dev";
			qcom,msm-dai-q6-dev-id = <16384>;
		};

		qcom,msm-dai-q6-sb-0-tx {
			compatible = "qcom,msm-dai-q6-dev";
			qcom,msm-dai-q6-dev-id = <16385>;
		};

		qcom,msm-dai-q6-afe-proxy-rx {
			compatible = "qcom,msm-dai-q6-dev";
			qcom,msm-dai-q6-dev-id = <241>;
		};

		qcom,msm-dai-q6-afe-proxy-tx {
			compatible = "qcom,msm-dai-q6-dev";
			qcom,msm-dai-q6-dev-id = <240>;
		};
	};

	qcom,smem@fa00000 {
		compatible = "qcom,smem";
		reg = <0xfa00000 0x200000>,
			<0xf9011000 0x1000>,
			<0xfc428000 0x4000>;
		reg-names = "smem", "irq-reg-base", "aux-mem1";

		qcom,smd-adsp {
			compatible = "qcom,smd";
			qcom,smd-edge = <1>;
			qcom,smd-irq-offset = <0x8>;
			qcom,smd-irq-bitmask = <0x100>;
			qcom,pil-string = "adsp";
			interrupts = <0 156 1>;
		};

		qcom,smsm-adsp {
			compatible = "qcom,smsm";
			qcom,smsm-edge = <1>;
			qcom,smsm-irq-offset = <0x8>;
			qcom,smsm-irq-bitmask = <0x200>;
			interrupts = <0 157 1>;
		};

		qcom,smd-rpm {
			compatible = "qcom,smd";
			qcom,smd-edge = <15>;
			qcom,smd-irq-offset = <0x8>;
			qcom,smd-irq-bitmask = <0x1>;
			interrupts = <0 168 1>;
			qcom,irq-no-suspend;
		};
	};

	tspp2: msm_tspp2@fc724000 {
		compatible = "qcom,msm_tspp2";
		cell-index = <0>;
		reg = <0xfc724000 0x7000>, /* MSM_TSPP2  */
		      <0xfc72b000 0x0200>, /* MSM_TSIF0 */
		      <0xfc72b200 0x0200>, /* MSM_TSIF1 */
		      <0xfc704000 0x20000>; /* MSM_TSPP2_BAM */
		reg-names = "MSM_TSPP2",
			"MSM_TSIF0",
			"MSM_TSIF1",
			"MSM_TSPP2_BAM";
		interrupts = <0 265 0>, /* TSPP2 */
			<0 263 0>, /* TSIF0 */
			<0 264 0>, /* TSIF1 */
			<0 262 0>; /* TSIF_BAM */
		interrupt-names = "TSPP2",
			"TSIF0",
			"TSIF1",
			"TSPP2_BAM";
		vdd-supply = <&gdsc_bcss>;
		qcom,msm-bus,name = "tspp2";
		qcom,msm-bus,num-cases = <3>;
		qcom,msm-bus,num-paths = <1>;
		qcom,msm-bus,vectors-KBps =
				<96 512 0 0>, /* No vote */
				<96 512 1024 1024>, /* Register access only. 8Mbps should be more than enough */
				<96 512 24576 61440>; /* Max. bandwidth required is 480Mbps */
		qcom,iommu-hlos-group = "bcast_hlos";
		qcom,iommu-hlos-partition = <0>;
		qcom,iommu-cpz-group = "bcast_cpz";
		qcom,iommu-cpz-partition = <0>;
	};

	dw: msm-demod-wrapper@fc600000 {
		compatible = "qcom,msm-demod-wrapper";
		reg = <0xfc600000 0xdd000>;
		reg-names = "demod-wrapper-base";
		vdd-supply = <&gdsc_bcss>;
		adc-supply = <&pma8084_l27>;
	};

	forza_sharedmem {
		compatible = "qcom,sharedmem-uio";
		reg = <0xfc6d1000 0x10000>;
		reg-names = "forza";
	};

	klm: msm-klm@fc560000 {
		compatible = "qcom,klm";
		reg = <0xfc560000 0x1000>, /* KLM registers */
		      <0xfc724000 0x7000>, /* TSPP2 registers */
		      <0xfc747000 0x1000>, /* KLM debug mode */
		      <0xfc748200 0x900>;  /* Key Tables */
		reg-names = "MSM_KLM", "MSM_BCSS_TSPP2", "MSM_BCSS_HLOS", "MSM_BCSS_KLM";
		vdd-supply = <&gdsc_bcss>;
	};

        qcom,msm-rng@f9bff000 {
		compatible = "qcom,msm-rng";
		reg = <0xf9bff000 0x200>;
		qcom,msm-bus,name = "msm-rng-noc";
		qcom,msm-bus,num-cases = <2>;
		qcom,msm-bus,num-paths = <1>;
		qcom,msm-bus,vectors-KBps =
				<1 618 0 0>,
				<1 618 0 800>;
        };

	qcom,tz-log@fe805720 {
		compatible = "qcom,tz-log";
		reg = <0xfe805720 0x1000>;
	};

	jtag_fuse: jtagfuse@fc4be024 {
		compatible = "qcom,jtag-fuse";
		reg = <0xfc4be024 0x8>;
		reg-names = "fuse-base";
	};

	qseecom: qcom,qseecom@cb00000 {
		compatible = "qcom,qseecom";
		reg = <0xcb00000 0x500000>;
		reg-names = "secapp-region";
		qcom,disk-encrypt-pipe-pair = <2>;
		qcom,hlos-ce-hw-instance = <1>;
		qcom,qsee-ce-hw-instance = <0>;
		qcom,msm-bus,name = "qseecom-noc";
		qcom,msm-bus,num-cases = <4>;
		qcom,msm-bus,num-paths = <1>;
		qcom,support-bus-scaling;
		qcom,msm-bus,vectors-KBps =
				<55 512 0 0>,
				<55 512 0 0>,
				<55 512 120000 1200000>,
				<55 512 393600 3936000>;
	};

	rpm_bus: qcom,rpm-smd {
			compatible = "qcom,rpm-smd";
			rpm-channel-name = "rpm_requests";
			rpm-channel-type = <15>; /* SMD_APPS_RPM */
	};

	qcom,msm-spss@fc5c3000 {
		#address-cells = <1>;
		#size-cells = <1>;
		ranges;
		compatible = "qcom,msm-spss";
		reg-names = "base";
		reg = <0xfc5c3000 0x1000>;

		geni_ir_1: qcom,msm-geni-ir@fc5c1000 {
			compatible = "qcom,msm-geni-ir";
			reg-names = "base";
			reg = <0xfc5c1000 0x1000>;
			interrupts = <0 284 0>, <0 285 0>;
			interrupt-names = "geni-ir-core-irq",
					  "geni-ir-wakeup-irq";
			qcom,geni-ir-gpio-tx = <&msmgpio 8 0>;
			qcom,geni-ir-gpio-rx = <&msmgpio 9 0>;
		};
	};

	qcom,venus@fdce0000 {
		compatible = "qcom,pil-tz-generic";
		reg = <0xfdce0000 0x4000>;

		vdd-supply = <&gdsc_venus>;
		proxy-reg-names = "vdd";
		clock-names = "core_clk", "iface_clk",
				"bus_clk", "mem_clk";
		proxy-clock-names = "core_clk", "iface_clk",
					"bus_clk", "mem_clk";

		qcom,msm-bus,name = "pil-venus";
		qcom,msm-bus,num-cases = <2>;
		qcom,msm-bus,num-paths = <1>;
		qcom,msm-bus,vectors-KBps =
				<63 512 0 0>,
				<63 512 0 304000>;

		qcom,pas-id = <9>;
		qcom,proxy-timeout-ms = <5000>;
		qcom,firmware-name = "venus";
	};

	qcom,lpass@fe200000 {
		compatible = "qcom,pil-tz-generic";
		reg = <0xfe200000 0x00100>;
		interrupts = <0 162 1>;

		vdd_cx-supply = <&pma8084_s8_corner>;
		proxy-reg-names = "vdd_cx";
		vdd_cx-uV-uA = <7 100000>;
		clock-names = "bus_clk", "xo";
		active-clock-names = "bus_clk";
		proxy-clock-names = "xo";

		qcom,pas-id = <1>;
		qcom,proxy-timeout-ms = <10000>;
		qcom,smem-id = <423>;
		qcom,firmware-name = "adsp";

		/* GPIO inputs from lpass */
		qcom,gpio-err-fatal = <&smp2pgpio_ssr_smp2p_2_in 0 0>;
		qcom,gpio-proxy-unvote = <&smp2pgpio_ssr_smp2p_2_in 2 0>;
		qcom,gpio-err-ready = <&smp2pgpio_ssr_smp2p_2_in 1 0>;
		qcom,gpio-stop-ack = <&smp2pgpio_ssr_smp2p_2_in 3 0>;

		/* GPIO output to lpass */
		qcom,gpio-force-stop = <&smp2pgpio_ssr_smp2p_2_out 0 0>;
	};

	demod: msm-demod@fc600000 {
		compatible = "qcom,msm-demod";
		reg = <0xfc600000 0xd0008>,<0xfc747000 0x1000>;
		reg-names = "msm-demod", "top-bcss";
		vdd-supply = <&gdsc_bcss>;
	};

	qcom,pil-vpu@fde0b000 {
		compatible = "qcom,pil-tz-generic";
		reg = <0xfde0b000 0x80>;

		vdd-supply = <&gdsc_vpu>;
		proxy-reg-names = "vdd";
		active-reg-names = "vdd";
		clock-names = "core_clk", "iface_clk", "bus_clk", "vdp_clk",
					"vdp_bus_clk", "sleep_clk", "maple_bus_clk";
		proxy-clock-names = "core_clk", "iface_clk", "bus_clk", "vdp_clk",
					"vdp_bus_clk", "sleep_clk", "maple_bus_clk";
		qcom,pas-id = <10>;
		qcom,proxy-timeout-ms = <10000>;
		qcom,firmware-name = "vpu";
	};

	qcom,pil-bcss {
		compatible = "qcom,pil-tz-generic";

		qcom,pas-id = <11>;
		qcom,proxy-timeout-ms = <0>;
		qcom,firmware-name = "bcss";
	};

	msm_vidc: qcom,vidc@fdc00000 {
		compatible = "qcom,msm-vidc";
		reg = <0xfdc00000 0xff000>;
		interrupts = <0 44 0>;
		qcom,hfi = "venus";
		qcom,ocmem-size = <524288>; /* 512 * 1024*/
		qcom,max-hw-load = <1281600>; /* Full 4k @ 30 + 1080p @ 30 */
		venus-supply = <&gdsc_venus>;
		venus-core0-supply = <&gdsc_venus_core0>;
		venus-core1-supply = <&gdsc_venus_core1>;
		qcom,clock-names= "core_clk", "core0_clk", "core1_clk", "iface_clk", "bus_clk", "mem_clk";
		qcom,clock-configs = <0x3 0x0 0x0 0x0 0x0 0x0>;
		qcom,load-freq-tbl = <979200 440000000>,
			<783360 440000000>,
			<489600 266670000>,
			<244800 133330000>;
		qcom,reg-presets = <0x800B0 0x00101001>,
			<0x800B0 0x00101001>,
			<0x800B4 0x00101010>,
			<0x800B8 0x10100010>,
			<0x800BC 0x00001010>,
			<0x800C0 0x1000100f>,
			<0x800C4 0x10000000>,
			<0x800C8 0x10001000>,
			<0x800CC 0x00001000>,
			<0x80070 0x00013FFF>,
			<0x80074 0x000000A4>,
			<0x800A8 0x00003FFF>,
			<0xe0020 0x5555556>,
			<0xe0024 0x5555556>,
			<0x80124 0x3>,
			<0x800E4 0x0>,
			<0x800D8 0x707>;
		qcom,buffer-type-tz-usage-table = <0x241 0x1>,
			<0x106 0x2>,
			<0x480 0x3>;
		qcom,vidc-iommu-domains {
			qcom,domain-ns {
				qcom,vidc-domain-phandle = <&venus_domain_ns>;
				qcom,vidc-partition-buffer-types = <0x7ff>,
					<0x800>;
			};
			qcom,domain-sec-bs {
				qcom,vidc-domain-phandle = <&venus_domain_sec_bitstream>;
				qcom,vidc-partition-buffer-types = <0x241>;
			};
			qcom,domain-sec-px {
				qcom,vidc-domain-phandle = <&venus_domain_sec_pixel>;
				qcom,vidc-partition-buffer-types = <0x106>;
			};
			qcom,domain-sec-np {
				qcom,vidc-domain-phandle = <&venus_domain_sec_non_pixel>;
				qcom,vidc-partition-buffer-types = <0x480>;
			};
		};
		qcom,msm-bus-clients {
			qcom,msm-bus-client@0 {
				qcom,msm-bus,name = "venc-ddr";
				qcom,msm-bus,num-cases = <8>;
				qcom,msm-bus,num-paths = <1>;
				qcom,msm-bus,vectors-KBps =
					<63 512 0 0>,
					<63 512 120000 302000>,
					<63 512 364000 302000>,
					<63 512 804000 302000>,
					<63 512 1608000 604000>,
					<63 512 2576000 967000>,
					<63 512 4680000 1404000>,
					<63 512 4988000 1496000>;
				qcom,bus-configs = <0x1000414>;
			};

			qcom,msm-bus-client@1 {
				qcom,msm-bus,name = "vdec-ddr";
				qcom,msm-bus,num-cases = <8>;
				qcom,msm-bus,num-paths = <1>;
				qcom,msm-bus,vectors-KBps =
					<63 512 0 0>,
					<63 512 208000 303000>,
					<63 512 536000 1600000>,
					<63 512 1012000 1600000>,
					<63 512 2024000 1600000>,
					<63 512 3240000 1600000>,
					<63 512 4048000 1600000>,
					<63 512 4264000 1600000>;
				qcom,bus-configs = <0xf0fcfff>;
			};

			qcom,msm-bus-client@2 {
				qcom,msm-bus,name = "venc-ocmem";
				qcom,msm-bus,num-cases = <8>;
				qcom,msm-bus,num-paths = <1>;
				qcom,msm-bus,vectors-KBps =
					<68 604 0 0>,
					<68 604 138000 1034000>,
					<68 604 414000 1034000>,
					<68 604 940000 1034000>,
					<68 604 1880000 2068000>,
					<68 604 3008000 3309000>,
					<68 604 3760000 4136000>,
					<68 604 4468000 2457000>;
				qcom,bus-configs = <0x1000414>;
			};

			qcom,msm-bus-client@3 {
				qcom,msm-bus,name = "vdec-ocmem";
				qcom,msm-bus,num-cases = <8>;
				qcom,msm-bus,num-paths = <1>;
				qcom,msm-bus,vectors-KBps =
					<68 604 0 0>,
					<68 604 176000 519000>,
					<68 604 456000 519000>,
					<68 604 864000 629000>,
					<68 604 1728000 1038000>,
					<68 604 2766000 1661000>,
					<68 604 3456000 2076000>,
					<68 604 3662000 2198000>;
				qcom,bus-configs = <0xf0fcfff>;
			};
		};
	};

	qcom,wfd {
		compatible = "qcom,msm-wfd";
	};

	tsens: tsens@fc4a8000 {
		compatible = "qcom,msm-tsens";
		reg = <0xfc4a8000 0x2000>,
		      <0xfc4bc000 0x1000>;
		reg-names = "tsens_physical", "tsens_eeprom_physical";
		interrupts = <0 184 0>;
		qcom,sensors = <11>;
		qcom,slope = <3200 3200 3200 3200 3200 3200 3200 3200 3200
				3200 3200>;
	};

	tsc: msm_tsc@fc74a000 {
		compatible = "qcom,msm-tsc";
		reg = <0xfc74a000 0x1110>;
		reg-names = "tsc-base";
		interrupts = <0 267 0>, /* cam-cmd */
					 <0 268 0>; /* card-detect */
		interrupt-names = "cam-cmd",
						  "card-detect";
		qcom,iommu-group = <&bcast_domain_hlos>;
		qcom,iommu-partition = <1>;
		vdd-supply = <&gdsc_bcss>;
		qcom,msm-bus,name = "tsc-bus";
		qcom,msm-bus,num-cases = <2>;
		qcom,msm-bus,num-paths = <1>;
		qcom,msm-bus,vectors-KBps = <96 512 0 0>, /* No vote */
									<96 512 448 896>; /* Max. 7Mbps */
		qcom,tsc-reset-cam-gpio = <&msm_gpio 138 0>;	/* reset-pin controller */
	};

	qcom,msm-thermal {
		compatible = "qcom,msm-thermal";
		qcom,sensor-id = <3>;
		qcom,poll-ms = <250>;
		qcom,limit-temp = <60>;
		qcom,temp-hysteresis = <10>;
		qcom,freq-step = <2>;
		qcom,freq-control-mask = <0xf>;
		qcom,core-limit-temp = <80>;
		qcom,core-temp-hysteresis = <10>;
		qcom,core-control-mask = <0xe>;
		qcom,hotplug-temp = <110>;
		qcom,hotplug-temp-hysteresis = <20>;
		qcom,cpu-sensors = "tsens_tz_sensor3", "tsens_tz_sensor4",
				"tsens_tz_sensor5", "tsens_tz_sensor6";
		qcom,freq-mitigation-temp = <110>;
		qcom,freq-mitigation-temp-hysteresis = <20>;
		qcom,freq-mitigation-value = <960000>;
		qcom,freq-mitigation-control-mask = <0x01>;
	};

	qcom,avtimer {
		compatible = "qcom,avtimer";
		reg = <0xfe0c900c 0x4>,
			<0xfe0c9010 0x4>;
		reg-names = "avtimer_lsb_addr", "avtimer_msb_addr";
	};

	qcom,cnss@0d400000 {
		compatible = "qcom,cnss";
		reg = <0x0d400000 0x200000>;
		reg-name = "ramdump";
		vdd-wlan-supply = <&wlan_vreg>;
	};

	spi_12: spi@f9968000 { /* BLSP2 QUP6 */
		compatible = "qcom,spi-qup-v2";
		#address-cells = <1>;
		#size-cells = <0>;
		reg-names = "spi_physical", "spi_bam_physical";
		reg = <0xf9968000 0x1000>,
		      <0xf9944000 0x19000>;
		interrupt-names = "spi_irq", "spi_bam_irq";
		interrupts = <0 106 0>, <0 239 0>;
		spi-max-frequency = <19200000>;
		qcom,gpio-mosi = <&msmgpio 87 0>;
		qcom,gpio-miso = <&msmgpio 88 0>;
		qcom,gpio-clk  = <&msmgpio 90 0>;
		qcom,gpio-cs0  = <&msmgpio 89 0>;

		qcom,infinite-mode = <0>;
		qcom,use-bam;
		qcom,ver-reg-exists;
		qcom,bam-consumer-pipe-index = <22>;
		qcom,bam-producer-pipe-index = <23>;
		qcom,master-id = <84>;
	};
};

&gdsc_venus {
	status = "ok";
};

&gdsc_venus_core0 {
	qcom,support-hw-trigger;
	status = "ok";
};

&gdsc_venus_core1 {
	qcom,support-hw-trigger;
	status = "ok";
};

&gdsc_mdss {
	clock-names = "core_clk", "lut_clk";
	status = "ok";
};

&gdsc_jpeg {
	status = "ok";
};

&gdsc_vpu {
	clock-names = "core_clk", "maple_clk", "bus_clk", "frc_xin_clk",
			   "hdmc_frcf_clk", "sdmc_frcs_clk", "sdme_frcf_clk",
			   "vproc_clk", "vdp_xin_clk";
	status = "ok";
};

&gdsc_oxili_gx {
	clock-names = "core_clk";
	status = "ok";
};

&gdsc_oxili_cx {
	status = "ok";
};

&gdsc_usb_hsic {
	status = "ok";
};

&gdsc_vcap {
	clock-names = "bus_clk", "vp_clk";
	status = "ok";
};

&gdsc_bcss {
	status = "ok";
};

&gdsc_pcie {
	status = "ok";
};

#include "msm-pma8084-rpm-regulator.dtsi"
#include "msm-pma8084.dtsi"
#include "mpq8092-regulator.dtsi"

&krait_regulator_pmic {
	status = "ok";

	qcom,ctl@2300 {
		reg = <0x2300 0x100>;
		status = "ok";
	};

	qcom,ps@2400 {
		reg = <0x2400 0x100>;
		status = "ok";
	};

	qcom,freq@2500 {
		reg = <0x2500 0x100>;
		status = "ok";
	};
};
